# S32K342_M7 register map
Vendor: NXP Semiconductors; File version: 1.5
CPU: CM7 r0p1, little endian, MPU, FPU, VTOR, 4 interrupt priority bits
Registers are 32-bit, read-write, reset 0x0 unless marked. A register's access mark holds for its fields unless they carry their own. Offsets are from the block's base; [hi:lo] are bit positions; {n}, {i} and the like mark numbered series.

## XBIC_AXBS — XBIC
Base 0x40204000
Same registers: XBIC_AXBS_PERI 0x40208000, XBIC_AXBS_TCM 0x40400000, XBIC_AXBS_EDMA 0x40404000
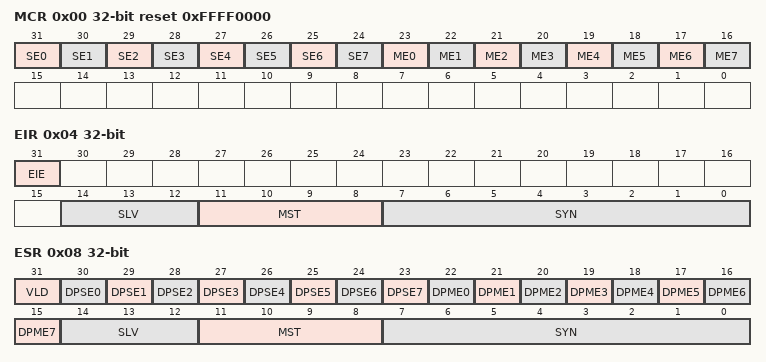
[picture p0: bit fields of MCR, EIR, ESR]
0x00 MCR reset 0xFFFF0000 — XBIC Module Control
  [31-n] SE{n} (n=0..6) — Slave port EDC Error Detection Enable
    0=DISABLED (Attribute integrity checking disabled for slave port {n}); 1=ENABLED (Attribute integrity checking enabled for slave port {n})
  [24] SE7 — Slave Port EDC Error Detection Enable
    0=DISABLED (Attribute integrity checking disabled for slave port 7); 1=ENABLED (Attribute integrity checking enabled for slave port 7)
  [23-n] ME{n} (n=0..7) — Master Port Enable For Feedback Integrity Check
    0=DISABLED (Feedback integrity checking disabled for master port {n}); 1=ENABLED (Feedback integrity checking enabled for master port {n})
0x04 EIR — XBIC Error Injection
  [31] EIE — Error Injection Enable
    0=DISABLED (Error injection disabled); 1=ENABLED (Error injection enabled)
  [14:12] SLV — Target Slave Port
  [11:8] MST — Target Master ID
  [7:0] SYN — Syndrome
0x08 ESR ro — XBIC Error Status
  [31] VLD — Error Status Valid
    0=NO_ERROR (No error detected-other fields of the ESR and EAR registers are invalid); 1=ERROR (Error detected-all fields of the ESR and EAR registers are valid)
  [30-n] DPSE{n} (n=0..7) — Data Phase Slave Port Error
    0=NO_ERROR (No feedback integrity error detected on slave port {n}); 1=ERROR (Feedback integrity error detected on slave port {n})
  [22-n] DPME{n} (n=0..7) — Data Phase Master Port Error
    0=NO_ERROR (No feedback integrity error detected on master port {n}); 1=ERROR (Feedback integrity error detected on master port {n})
  [14:12] SLV — Slave Port
  [11:8] MST — Master ID
  [7:0] SYN — Syndrome
0x0C EAR ro — XBIC Error Address
  [31:0] ADDR — Error Address

## EDMA — DMA MP
Base 0x4020C000
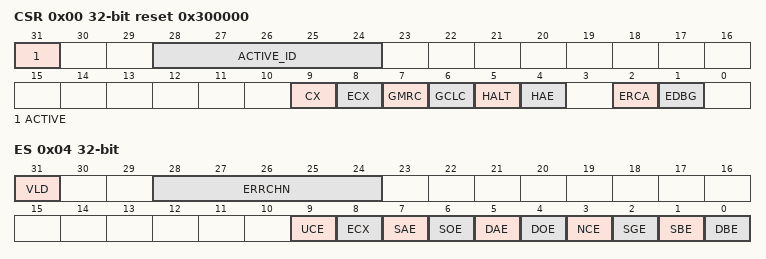
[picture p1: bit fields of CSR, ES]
0x00 CSR reset 0x300000 — Management Page Control
  [31] ACTIVE ro — DMA Active Status
    0=eDMA is idle; 1=eDMA is executing a channel
  [28:24] ACTIVE_ID ro — Active Channel ID
  [9] CX — Cancel Transfer
    0=Normal operation; 1=Cancel the remaining data transfer
  [8] ECX — Cancel Transfer With Error
    0=Normal operation; 1=Cancel the remaining data transfer
  [7] GMRC — Global Master ID Replication Control
    0=Master ID replication disabled for all channels; 1=Master ID replication available and controlled by each channel's CHn_SBR[EMI] setting
  [6] GCLC — Global Channel Linking Control
    0=Channel linking disabled for all channels; 1=Channel linking available and controlled by each channel's link settings
  [5] HALT — Halt DMA Operations
    0=Normal operation; 1=Stall the start of any new channels
  [4] HAE — Halt After Error
    0=Normal operation; 1=Any error causes the HALT field to be set to 1
  [2] ERCA — Enable Round Robin Channel Arbitration
    0=Round-robin channel arbitration disabled; 1=Round-robin channel arbitration enabled
  [1] EDBG — Enable Debug
    0=Debug mode disabled; 1=Debug mode is enabled
0x04 ES ro — Management Page Error Status
  [31] VLD — Valid
    0=No ERR fields are set to 1; 1=At least one ERR field is set to 1, indicating a valid error exists that software has not cleared
  [28:24] ERRCHN — Error Channel Number or Canceled Channel Number
  [9] UCE — Uncorrectable TCD Error During Channel Execution
    0=No uncorrectable ECC error; 1=Last recorded error was an uncorrectable TCD RAM error
  [8] ECX — Transfer Canceled
    0=No canceled transfers; 1=Last recorded entry was a canceled transfer by the error cancel transfer input
  [7] SAE — Source Address Error
    0=No source address configuration error; 1=Last recorded error was a configuration error detected in the TCDn_SADDR field
  [6] SOE — Source Offset Error
    0=No source offset configuration error; 1=Last recorded error was a configuration error detected in the TCDn_SOFF field
  [5] DAE — Destination Address Error
    0=No destination address configuration error; 1=Last recorded error was a configuration error detected in the TCDn_DADDR field
  [4] DOE — Destination Offset Error
    0=No destination offset configuration error; 1=Last recorded error was a configuration error detected in the TCDn_DOFF field
  [3] NCE — NBYTES/CITER Configuration Error
    0=No NBYTES/CITER configuration error; 1=The last recorded error was NBYTES equal to zero or a CITER not equal to BITER error
  [2] SGE — Scatter/Gather Configuration Error
    0=No scatter/gather configuration error; 1=Last recorded error was a configuration error detected in the TCDn_DLAST_SGA field
  [1] SBE — Source Bus Error
    0=No source bus error; 1=Last recorded error was a bus error on a source read
  [0] DBE — Destination Bus Error
    0=No destination bus error; 1=Last recorded error was a bus error on a destination write
0x08 INT ro — Management Page Interrupt Request Status
  [31:0] INT — Interrupt Request Status
0x0C HRS ro — Management Page Hardware Request Status
  [31:0] HRS — Hardware Request Status
{0x100+4i} CH_GRPRI[{i}] (i=0..31) — Channel Arbitration Group
  [4:0] GRPRI — Arbitration Group For Channel n

## Notices in the file
Copyright 2016-2021 NXP
NXP Confidential. This software is owned or controlled by NXP and may only be
used strictly in accordance with the applicable license terms. By expressly
accepting such terms or by downloading, installing, activating and/or otherwise
using the software, you are agreeing that you have read, and that you agree to
comply with and are bound by, such license terms. If you do not agree to be
bound by the applicable license terms, then you may not retain, install,
activate or otherwise use the software. The production use license in
Section 2.3 is expressly granted for this software.
